# AE822FA0E5597BS0_CM55_HE_View register map
Vendor: Alif Semiconductor; Series: E8; File version: 1.0
CPU: CM55 r1p0, selectable endian, MPU, FPU, double-precision FPU, DSP, VTOR, 8 interrupt priority bits, 1 SAU regions
Registers are 32-bit, read-write, reset 0x0 unless marked. A register's access mark holds for its fields unless they carry their own. Offsets are from the block's base; [hi:lo] are bit positions; {n}, {i} and the like mark numbered series.

## CSI
Base 0x49033000
0x00 CSI_VERSION ro reset 0x30313534 — Module Version Code Register
  [31:0] VERSION — Module version code
0x04 CSI_N_LANES reset 0x1 — Lane Configuration Register
  [2:0] N_LANES — This can only be updated when the PHY lane is in Stop state. Number of active data lanes:
    0=1 Data Lane; 1=2 Data Lanes
0x08 CSI_CSI2_RESETN — CSI Controller Reset Control Register
  [0] CSI2_RESETN — CSI controller reset output. Active low.
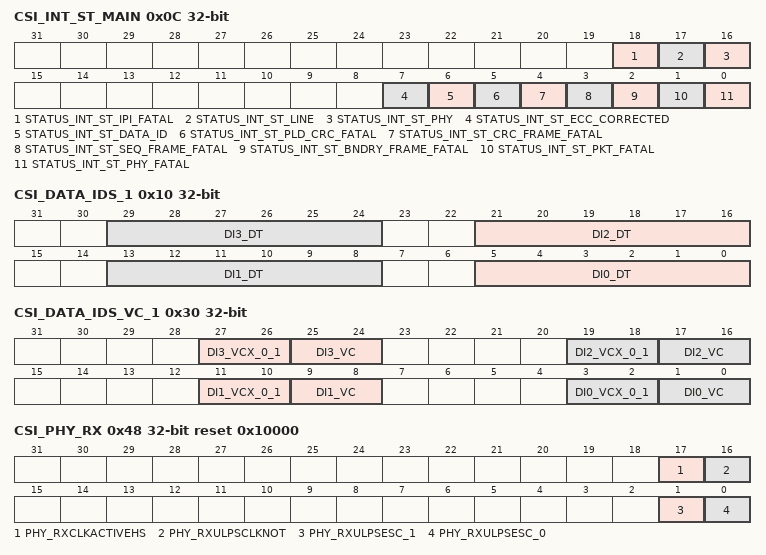
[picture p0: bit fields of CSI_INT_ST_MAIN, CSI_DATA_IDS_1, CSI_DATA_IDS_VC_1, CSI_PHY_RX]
0x0C CSI_INT_ST_MAIN ro — Main Interrupt Status Register
  [18] STATUS_INT_ST_IPI_FATAL read-clears — Status of INT_ST_IPI_FATAL.
  [17] STATUS_INT_ST_LINE read-clears — Status of INT_ST_LINE.
  [16] STATUS_INT_ST_PHY read-clears — Status of INT_ST_PHY.
  [7] STATUS_INT_ST_ECC_CORRECTED read-clears — Status of INT_ST_ECC_CORRECTED.
  [6] STATUS_INT_ST_DATA_ID read-clears — Status of INT_ST_DATA_ID.
  [5] STATUS_INT_ST_PLD_CRC_FATAL read-clears — Status of INT_ST_PLD_CRC_FATAL.
  [4] STATUS_INT_ST_CRC_FRAME_FATAL read-clears — Status of INT_ST_CRC_FRAME_FATAL.
  [3] STATUS_INT_ST_SEQ_FRAME_FATAL read-clears — Status of INT_ST_SEQ_FRAME_FATAL.
  [2] STATUS_INT_ST_BNDRY_FRAME_FATAL read-clears — Status of INT_ST_BNDRY_FRAME_FATAL.
  [1] STATUS_INT_ST_PKT_FATAL read-clears — Status of INT_ST_PKT_FATAL.
  [0] STATUS_INT_ST_PHY_FATAL read-clears — Status of INT_ST_PHY_FATAL.
0x10 CSI_DATA_IDS_1 — DT Data ID Monitors Configuration Register
  [8n+5:8n] DI{n}_DT (n=0..3) — Data type for programmed Data ID {n}.
0x30 CSI_DATA_IDS_VC_1 — VC Data ID Monitors Configuration Register
  [27:26] DI3_VCX_0_1 — Virtual channel extension for programmed Data ID 3.
  [8n+1:8n] DI{n}_VC (n=0..3) — Virtual channel for programmed Data ID {n}.
  [19:18] DI2_VCX_0_1 — Virtual channel extension for programmed Data ID 2.
  [11:10] DI1_VCX_0_1 — Virtual channel extension for programmed Data ID 1.
  [3:2] DI0_VCX_0_1 — Virtual channel extension for programmed data ID 0.
0x40 CSI_PHY_SHUTDOWNZ — PHY Shutdown Control Register
  [0] PHY_SHUTDOWNZ — Shutdown input. This line is used to place the complete PHY module in power down. All analog blocks are in power down mode and digital logic is cleared. Active low.
0x44 CSI_DPHY_RSTZ — PHY Reset Control Register
  [0] DPHY_RSTZ — PHY reset output. Active low.
0x48 CSI_PHY_RX ro reset 0x10000 — PHY RX Signals Status Register
  [17] PHY_RXCLKACTIVEHS — Indicates that D-PHY clock lane is actively receiving a DDR clock.
  [16] PHY_RXULPSCLKNOT — Active low. This signal indicates that D-PHY Clock Lane module has entered the Ultra Low Power State.
  [1] PHY_RXULPSESC_1 — Lane module 1 has entered the Ultra Low Power mode.
  [0] PHY_RXULPSESC_0 — Lane module 0 has entered the Ultra Low Power mode.
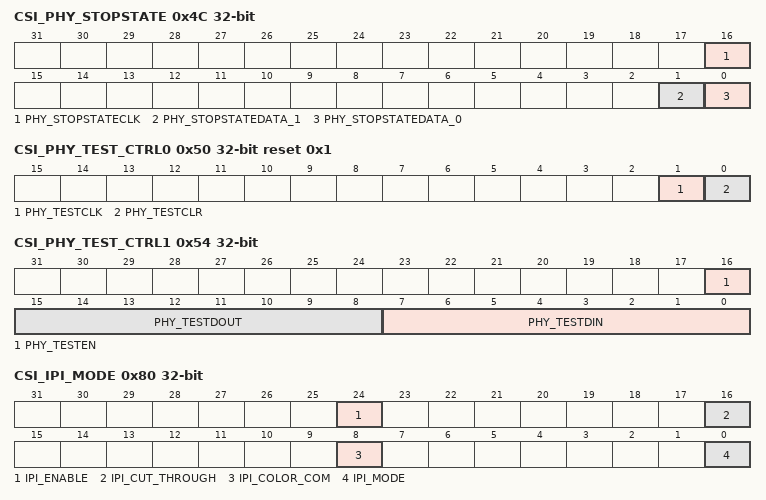
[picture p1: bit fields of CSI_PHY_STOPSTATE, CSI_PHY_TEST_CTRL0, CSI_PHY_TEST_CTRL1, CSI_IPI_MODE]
0x4C CSI_PHY_STOPSTATE ro — PHY STOPSTATE Signal Status Register
  [16] PHY_STOPSTATECLK — D-PHY Clock lane in Stop state.
  [1] PHY_STOPSTATEDATA_1 — Data lane 1 in Stop state.
  [0] PHY_STOPSTATEDATA_0 — Data lane 0 in Stop state.
0x50 CSI_PHY_TEST_CTRL0 reset 0x1 — PHY Test Control 0 Register
  [1] PHY_TESTCLK — Clock to capture TESTDIN bus contents into the PHY module, with TESTEN signal controlling the operation selection.
  [0] PHY_TESTCLR — When active, performs test interface initialization. Active high.
0x54 CSI_PHY_TEST_CTRL1 — PHY Test Control 1 Register
  [16] PHY_TESTEN — When asserted high, it configures an address write operation on the falling edge of TESTCLK. When asserted low, it configures a data write operation on the rising edge of TESTCLK.
  [15:8] PHY_TESTDOUT ro — Test interface 8-bit data output for reading data and other probing functionalities.
  [7:0] PHY_TESTDIN — Test interface 8-bit data input for programming internal registers and accessing test functionalities.
0x80 CSI_IPI_MODE — IPI Mode Selection Register
  [24] IPI_ENABLE — This register enables the interface.
  [16] IPI_CUT_THROUGH — This field indicates Cut-Through mode state:
    0=Cut-Through mode inactive; 1=Cut-Through mode active
  [8] IPI_COLOR_COM — This field indicates if color mode components are delivered as follows:
    0=48-bit interface; 1=16-bit interface
  [0] IPI_MODE — This field indicates the video mode transmission type as follows:
    0=Camera timing; 1=Controller timing
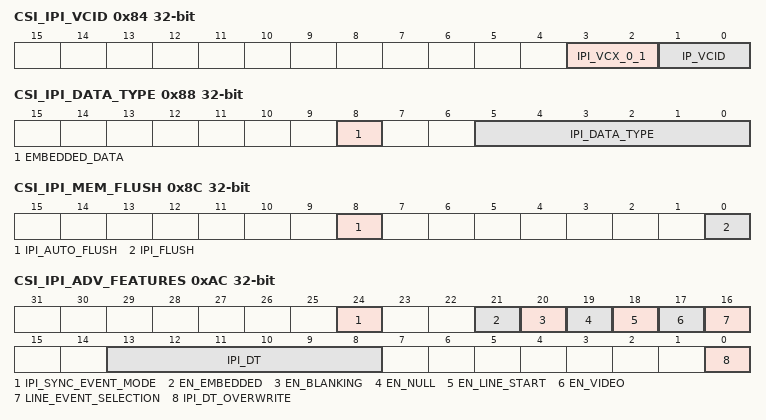
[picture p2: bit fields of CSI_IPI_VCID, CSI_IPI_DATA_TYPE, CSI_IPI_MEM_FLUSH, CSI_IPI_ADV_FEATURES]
0x84 CSI_IPI_VCID — IPI VC Selection Register
  [3:2] IPI_VCX_0_1 — Virtual channel extension of data to be processed by pixel interface.
  [1:0] IP_VCID — Virtual channel of data to be processed by pixel interface.
0x88 CSI_IPI_DATA_TYPE — IPI DT Selection Register
  [8] EMBEDDED_DATA — For Camera Timing Mode, this bit enables embedded data processing on IPI 1 interface.
  [5:0] IPI_DATA_TYPE — Data type of data to be processed by pixel interface 1.
0x8C CSI_IPI_MEM_FLUSH — IPI Memory Flush Control Register
  [8] IPI_AUTO_FLUSH — Memory is automatically flushed at each Frame Start.
  [0] IPI_FLUSH — Flush IPI memory. This bit is auto cleared.
0x90 CSI_IPI_HSA_TIME — IPI HSA Configuration Register
  [11:0] IPI_HSA_TIME — This field configures the HSA period in PIXCLK cycles.
0x94 CSI_IPI_HBP_TIME — IPI HBP Configuration Register
  [11:0] IPI_HBP_TIME — This field configures the HBP period in PIXCLK cycles.
0x98 CSI_IPI_HSD_TIME — IPI HSD Configuration Register
  [11:0] IPI_HSD_TIME — This field configures the Horizontal Sync Delay period in PIXCLK cycles.
0x9C CSI_IPI_HLINE_TIME — IPI HLINE Configuration Register
  [14:0] IPI_HLINE_TIME — This field configures the size of the line time counted in PIXCLK cycles.
0xA0 CSI_IPI_SOFTRSTN reset 0x1 — IPI Reset Control Register
  [0] IPI_SOFTRSTN — This field resets IPI. Active low.
0xAC CSI_IPI_ADV_FEATURES — IPI Advanced Features Configuration Register
  [24] IPI_SYNC_EVENT_MODE — For Camera Timing Mode:
    0=Frame Start does not trigger any sync event; 1=Legacy mode. Frame Start triggers a sync event.
  [21] EN_EMBEDDED — This field allows the use of embedded packets for IPI synchronization events.
  [20] EN_BLANKING — This field allows the use of blanking packets for IPI synchronization events.
  [19] EN_NULL — This field allows the use of null packets for IPI synchronization events.
  [18] EN_LINE_START — This field allows the use of line start packets for IPI synchronization events.
  [17] EN_VIDEO — This field allows the use of video packets for IPI synchronization events.
  [16] LINE_EVENT_SELECTION — For Camera Timing Mode, this field allows manual selection of the Packet for line delimiter as follows:
    0=Controller selects it automatically; 1=Select packets from list programmed in bits [21-17] of this register
  [13:8] IPI_DT — Data type to overwrite.
  [0] IPI_DT_OVERWRITE — Ignore Data type of the header using the programmed Data type for decoding.
0xB0 CSI_IPI_VSA_LINES — IPI VSA Configuration Register
  [9:0] IPI_VSA_LINES — This field configures the VSA period measured in number of horizontal lines.
0xB4 CSI_IPI_VBP_LINES — IPI VBP Configuration Register
  [9:0] IPI_VBP_LINES — This field configures the VBP period measured in number of horizontal lines.
0xB8 CSI_IPI_VFP_LINES — IPI VFP Configuration Register
  [9:0] IPI_VFP_LINES — This field configures the VFP period measured in number of horizontal lines.
0xBC CSI_IPI_VACTIVE_LINES — IPI VACTIVE Configuration Register
  [13:0] IPI_VACTIVE_LINES — This field configures the Vertical Active period measured in number of horizontal lines.
0xC8 CSI_VC_EXTENSION — VC Extension Configuration Register
  [0] VCX — This field indicates status of virtual channel extension:
    0=Virtual channel extension is enabled; 1=Legacy mode. Virtual channel extension is disabled.
0xCC CSI_PHY_CAL ro — PHY CALIBRATION Signal Status Register
  [0] RXSKEWCALHS read-clears — A low-to-high transition on RXSKEWCALHS signal means that the PHY has initiated the deskew calibration.
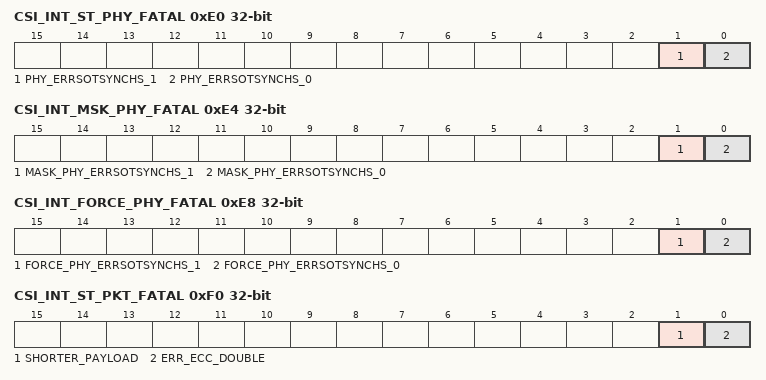
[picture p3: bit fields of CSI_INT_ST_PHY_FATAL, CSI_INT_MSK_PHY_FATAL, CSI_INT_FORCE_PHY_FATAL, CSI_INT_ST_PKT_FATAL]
0xE0 CSI_INT_ST_PHY_FATAL ro — PHY Packet Discarded Interrupt Status Register
  [1] PHY_ERRSOTSYNCHS_1 read-clears — Start of transmission error on data lane 1 (no synchronization achieved).
  [0] PHY_ERRSOTSYNCHS_0 read-clears — Start of transmission error on data lane 0 (no synchronization achieved).
0xE4 CSI_INT_MSK_PHY_FATAL — PHY Packet Discarded Interrupt Mask Register
  [1] MASK_PHY_ERRSOTSYNCHS_1 — Mask for PHY_ERRSOTSYNCHS_1.
  [0] MASK_PHY_ERRSOTSYNCHS_0 — Mask for PHY_ERRSOTSYNCHS_0.
0xE8 CSI_INT_FORCE_PHY_FATAL — PHY Packet Discarded Interrupt Force Register
  [1] FORCE_PHY_ERRSOTSYNCHS_1, [0] FORCE_PHY_ERRSOTSYNCHS_0
0xF0 CSI_INT_ST_PKT_FATAL ro — PHY Packet Construction Interrupt Status Register
  [1] SHORTER_PAYLOAD read-clears — D-PHY mode: Reported greater WC than received, unrecoverable.
  [0] ERR_ECC_DOUBLE read-clears — D-PHY mode: Header ECC contains at least 2 errors, unrecoverable.
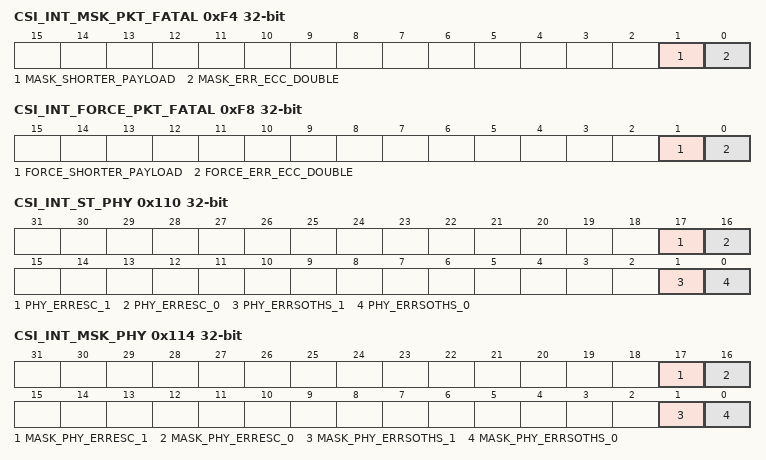
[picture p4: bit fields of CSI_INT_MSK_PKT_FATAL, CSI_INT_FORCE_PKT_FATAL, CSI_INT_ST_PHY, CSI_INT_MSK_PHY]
0xF4 CSI_INT_MSK_PKT_FATAL — PHY Packet Construction Interrupt Mask Register
  [1] MASK_SHORTER_PAYLOAD — Mask for SHORTER_PAYLOAD.
  [0] MASK_ERR_ECC_DOUBLE — Mask for ERR_ECC_DOUBLE.
0xF8 CSI_INT_FORCE_PKT_FATAL — PHY Packet Construction Interrupt Force Register
  [1] FORCE_SHORTER_PAYLOAD, [0] FORCE_ERR_ECC_DOUBLE
0x110 CSI_INT_ST_PHY ro — PHY Interrupt Status Register
  [17] PHY_ERRESC_1 read-clears — Escape Entry Error on data lane 1.
  [16] PHY_ERRESC_0 read-clears — Escape Entry Error on data lane 0.
  [1] PHY_ERRSOTHS_1 read-clears — Start of transmission error on data lane 1 (synchronization can still be achieved).
  [0] PHY_ERRSOTHS_0 read-clears — Start of transmission error on data lane 0 (synchronization can still be achieved).
0x114 CSI_INT_MSK_PHY — PHY Interrupt Mask Register
  [17] MASK_PHY_ERRESC_1 — Mask for PHY_ERRESC_1.
  [16] MASK_PHY_ERRESC_0 — Mask for PHY_ERRESC_0.
  [1] MASK_PHY_ERRSOTHS_1 — Mask for PHY_ERRSOTHS_1.
  [0] MASK_PHY_ERRSOTHS_0 — Mask for PHY_ERRSOTHS_0.
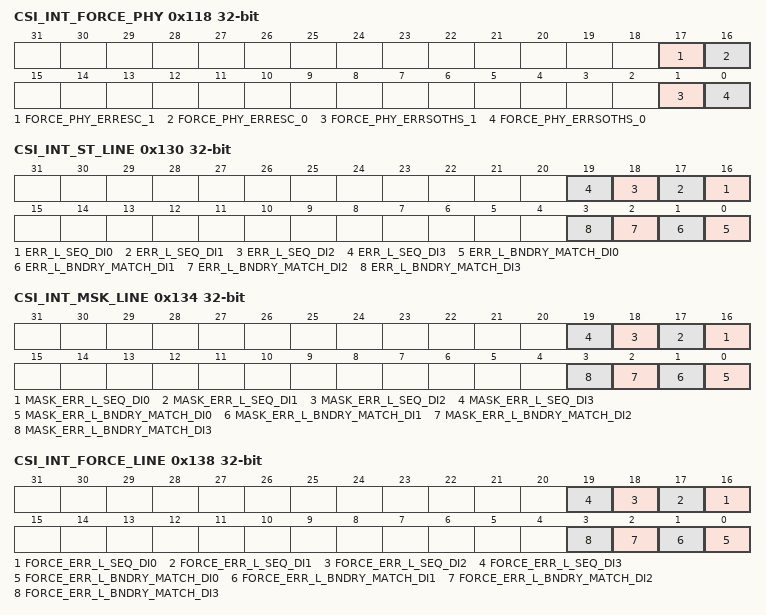
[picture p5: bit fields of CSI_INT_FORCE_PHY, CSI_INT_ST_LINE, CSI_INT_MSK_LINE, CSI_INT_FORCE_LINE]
0x118 CSI_INT_FORCE_PHY — PHY Interrupt Force Register
  [17] FORCE_PHY_ERRESC_1, [16] FORCE_PHY_ERRESC_0, [1] FORCE_PHY_ERRSOTHS_1, [0] FORCE_PHY_ERRSOTHS_0
0x130 CSI_INT_ST_LINE ro — PHY Line Construction Interrupt Status Register
  [n+16] ERR_L_SEQ_DI{n} read-clears (n=0..3) — Error in the sequence of lines for VC{n} and DT{n}.
  [n] ERR_L_BNDRY_MATCH_DI{n} read-clears (n=0..3) — Error matching line start with line end for VC{n} and DT{n}.
0x134 CSI_INT_MSK_LINE — PHY Line Construction Interrupt Mask Register
  [n+16] MASK_ERR_L_SEQ_DI{n} (n=0..3) — Mask for ERR_L_SEQ_DI{n}.
  [n] MASK_ERR_L_BNDRY_MATCH_DI{n} (n=0..3) — Mask for ERR_L_BNDRY_MATCH_DI{n}.
0x138 CSI_INT_FORCE_LINE — PHY Line Construction Interrupt Force Register
  [n+16] FORCE_ERR_L_SEQ_DI{n} (n=0..3), [n] FORCE_ERR_L_BNDRY_MATCH_DI{n} (n=0..3)
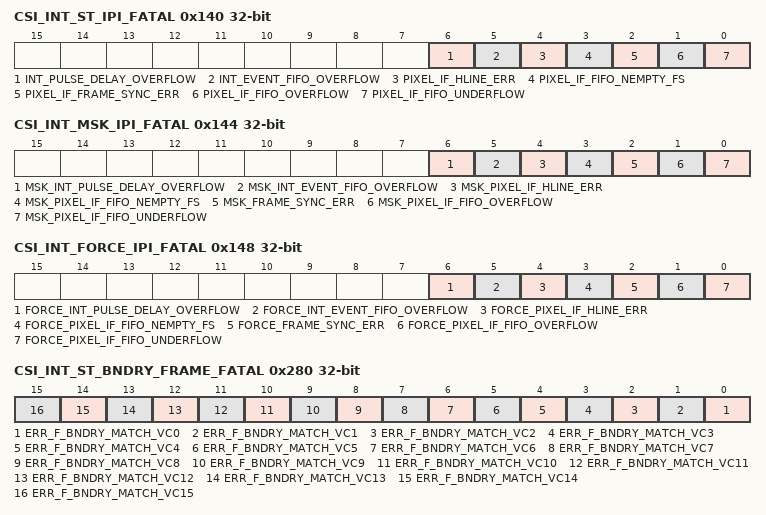
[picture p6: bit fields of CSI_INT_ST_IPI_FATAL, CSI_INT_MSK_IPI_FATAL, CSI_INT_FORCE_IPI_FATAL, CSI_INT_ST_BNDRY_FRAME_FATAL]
0x140 CSI_INT_ST_IPI_FATAL ro — IPI Interface Interrupt Status Register
  [6] INT_PULSE_DELAY_OVERFLOW read-clears — Reporting internal FIFO overflow on pulse delay block.
  [5] INT_EVENT_FIFO_OVERFLOW read-clears — Reporting internal FIFO overflow during IPI data processing.
  [4] PIXEL_IF_HLINE_ERR read-clears — Horizontal line time error (only available in Controller timing mode).
  [3] PIXEL_IF_FIFO_NEMPTY_FS read-clears — Controller timing mode: The FIFO of pixel interface is not empty at the start of a new frame. If this is expected this interrupt should be masked. Camera timing mode: The FIFO of pixel interface is not empty at the start of a new frame. There are some scenarios where synchronization events of new frame can be lost on IPI interface.
  [2] PIXEL_IF_FRAME_SYNC_ERR read-clears — Whenever in Controller timing mode, notifies if a new frame is received but previous has not been completed.
  [1] PIXEL_IF_FIFO_OVERFLOW read-clears — The FIFO of pixel interface has lost information because some data arrived and FIFO is already full.
  [0] PIXEL_IF_FIFO_UNDERFLOW read-clears — The FIFO has become empty before the expected number of pixels (calculated from the packet header) could be extracted to the pixel interface.
0x144 CSI_INT_MSK_IPI_FATAL — IPI Interface Interrupt Mask Register
  [6] MSK_INT_PULSE_DELAY_OVERFLOW — Mask for INT_PULSE_DELAY_OVERFLOW.
  [5] MSK_INT_EVENT_FIFO_OVERFLOW — Mask for INT_EVENT_FIFO_OVERFLOW.
  [4] MSK_PIXEL_IF_HLINE_ERR — Mask for PIXEL_IF_HLINE_ERR.
  [3] MSK_PIXEL_IF_FIFO_NEMPTY_FS — Mask for PIXEL_IF_FIFO_NEMPTY_FS.
  [2] MSK_FRAME_SYNC_ERR — Mask for PIXEL_IF_FRAME_SYNC_ERR.
  [1] MSK_PIXEL_IF_FIFO_OVERFLOW — Mask for PIXEL_IF_FIFO_OVERFLOW.
  [0] MSK_PIXEL_IF_FIFO_UNDERFLOW — Mask for PIXEL_IF_FIFO_UNDERFLOW.
0x148 CSI_INT_FORCE_IPI_FATAL — IPI Interface Interrupt Force Register
  [6] FORCE_INT_PULSE_DELAY_OVERFLOW — Force for INT_INT_PULSE_DELAY_OVERFLOW.
  [5] FORCE_INT_EVENT_FIFO_OVERFLOW — Force for INT_EVENT_FIFO_OVERFLOW.
  [4] FORCE_PIXEL_IF_HLINE_ERR — Force for PIXEL_IF_HLINE_ERR.
  [3] FORCE_PIXEL_IF_FIFO_NEMPTY_FS — Force for PIXEL_IF_FIFO_NEMPTY_FS.
  [2] FORCE_FRAME_SYNC_ERR — Force for FRAME_SYNC_ERR.
  [1] FORCE_PIXEL_IF_FIFO_OVERFLOW — Force for PIXEL_IF_FIFO_OVERFLOW.
  [0] FORCE_PIXEL_IF_FIFO_UNDERFLOW — Force for PIXEL_IF_FIFO_UNDERFLOW.
0x280 CSI_INT_ST_BNDRY_FRAME_FATAL ro — Frame Boundary Error Interrupt Status Register
  [n] ERR_F_BNDRY_MATCH_VC{n} read-clears (n=0..15) — Error matching Frame Start with Frame End for VC{n}.
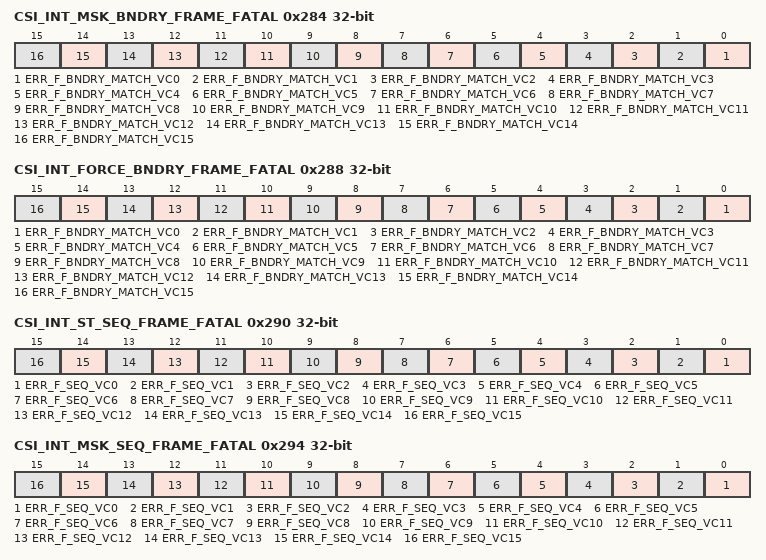
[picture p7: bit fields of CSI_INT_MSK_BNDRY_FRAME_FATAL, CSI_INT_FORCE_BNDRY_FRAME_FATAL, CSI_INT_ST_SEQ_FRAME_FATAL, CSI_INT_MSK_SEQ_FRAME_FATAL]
0x284 CSI_INT_MSK_BNDRY_FRAME_FATAL — Frame Boundary Error Interrupt Mask Register
  [n] ERR_F_BNDRY_MATCH_VC{n} (n=0..15) — Mask for ERR_F_BNDRY_MATCH_VC{n}.
0x288 CSI_INT_FORCE_BNDRY_FRAME_FATAL — Frame Boundary Error Interrupt Force Register
  [n] ERR_F_BNDRY_MATCH_VC{n} (n=0..15) — Force ERR_F_BNDRY_MATCH_VC{n}.
0x290 CSI_INT_ST_SEQ_FRAME_FATAL ro — Frame Sequence Error Interrupt Status Register
  [n] ERR_F_SEQ_VC{n} read-clears (n=0..15) — Incorrect Frame sequence detected in VC{n}.
0x294 CSI_INT_MSK_SEQ_FRAME_FATAL — Frame Sequence Error Interrupt Mask Register
  [n] ERR_F_SEQ_VC{n} (n=0..15) — Mask for ERR_F_SEQ_VC{n}.
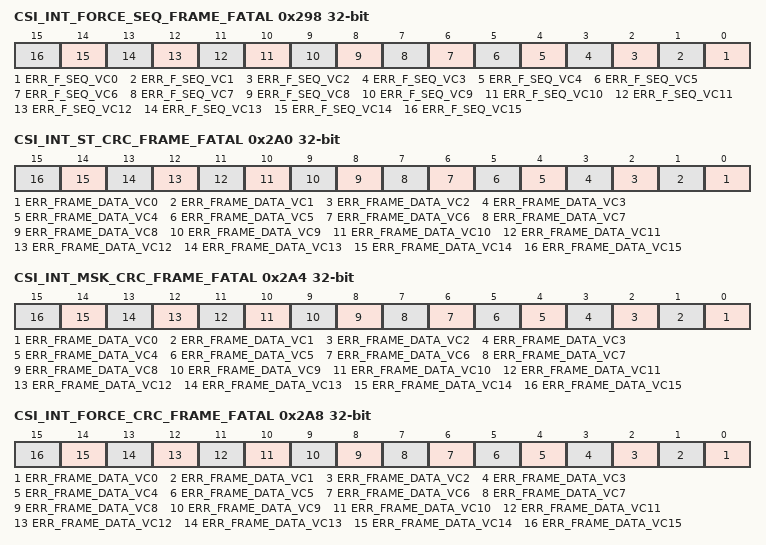
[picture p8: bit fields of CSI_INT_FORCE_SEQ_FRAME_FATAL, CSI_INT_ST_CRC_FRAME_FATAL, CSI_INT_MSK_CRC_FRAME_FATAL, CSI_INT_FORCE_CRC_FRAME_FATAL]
0x298 CSI_INT_FORCE_SEQ_FRAME_FATAL — Frame Sequence Error Interrupt Force Register
  [n] ERR_F_SEQ_VC{n} (n=0..15) — Force ERR_F_SEQ_VC{n}.
0x2A0 CSI_INT_ST_CRC_FRAME_FATAL ro — Frame CRC Error Interrupt Status Register
  [n] ERR_FRAME_DATA_VC{n} read-clears (n=0..15) — Last received Frame in VC{n}, had at least one CRC error.
0x2A4 CSI_INT_MSK_CRC_FRAME_FATAL — Frame CRC Error Interrupt Mask Register
  [n] ERR_FRAME_DATA_VC{n} (n=0..15) — Mask for ERR_FRAME_DATA_VC{n}.
0x2A8 CSI_INT_FORCE_CRC_FRAME_FATAL — Frame CRC Error Interrupt Force Register
  [n] ERR_FRAME_DATA_VC{n} (n=0..15) — Force ERR_FRAME_DATA_VC{n}.
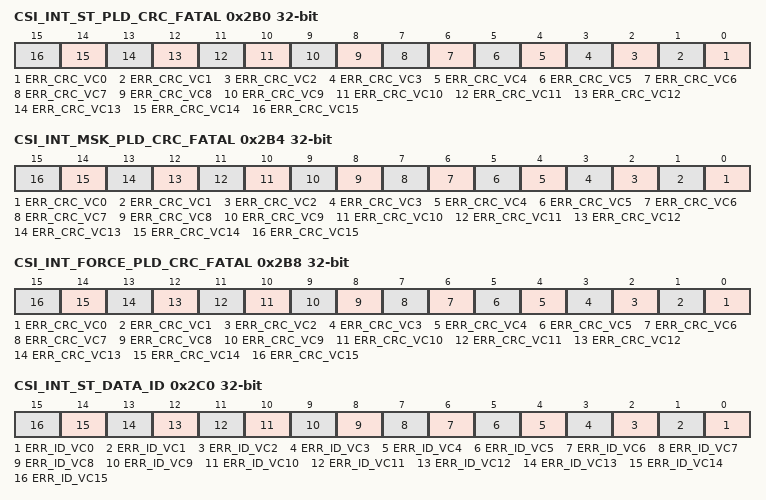
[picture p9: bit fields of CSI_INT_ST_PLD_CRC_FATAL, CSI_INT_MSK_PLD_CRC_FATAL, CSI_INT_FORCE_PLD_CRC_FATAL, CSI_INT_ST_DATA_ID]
0x2B0 CSI_INT_ST_PLD_CRC_FATAL ro — Frame Payload Error Interrupt Status Register
  [n] ERR_CRC_VC{n} read-clears (n=0..15) — Payload Checksum error detected on VC{n}.
0x2B4 CSI_INT_MSK_PLD_CRC_FATAL — Frame Payload Error Interrupt Mask Register
  [n] ERR_CRC_VC{n} (n=0..15) — Mask for ERR_CRC_VC{n}.
0x2B8 CSI_INT_FORCE_PLD_CRC_FATAL — Frame Payload Error Interrupt Force Register
  [n] ERR_CRC_VC{n} (n=0..15) — Force ERR_CRC_VC{n}.
0x2C0 CSI_INT_ST_DATA_ID ro — DT Error Interrupt Status Register
  [n] ERR_ID_VC{n} read-clears (n=0..15) — Unrecognized or unimplemented data type detected in VC{n}.
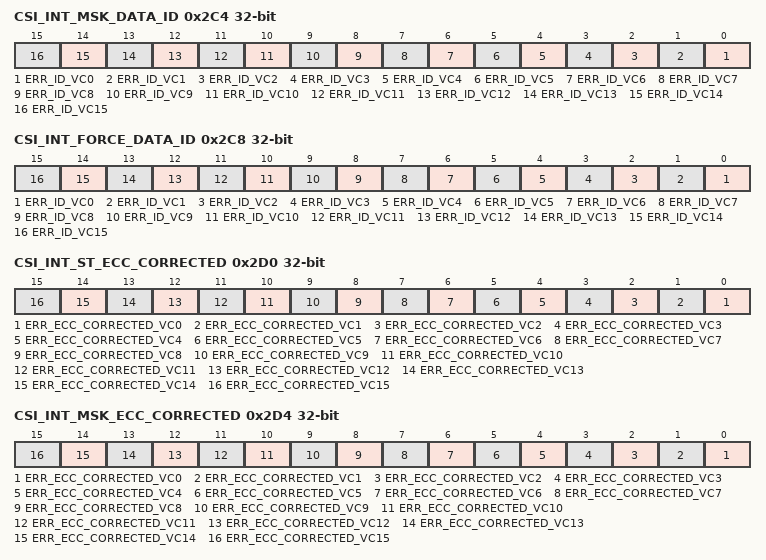
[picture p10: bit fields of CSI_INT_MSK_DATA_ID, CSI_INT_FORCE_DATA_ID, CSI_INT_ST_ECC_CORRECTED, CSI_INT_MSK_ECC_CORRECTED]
0x2C4 CSI_INT_MSK_DATA_ID — DT Error Interrupt Mask Register
  [n] ERR_ID_VC{n} (n=0..15) — Mask for ERR_ID_VC{n}.
0x2C8 CSI_INT_FORCE_DATA_ID — DT Error Interrupt Force Register
  [n] ERR_ID_VC{n} (n=0..15) — Force ERR_ID_VC{n}.
0x2D0 CSI_INT_ST_ECC_CORRECTED ro — ECC Interrupt Status Register
  [n] ERR_ECC_CORRECTED_VC{n} read-clears (n=0..15) — D-PHY mode: Header error detected and corrected on VC{n}.
0x2D4 CSI_INT_MSK_ECC_CORRECTED — ECC Interrupt Mask Register
  [n] ERR_ECC_CORRECTED_VC{n} (n=0..15) — Mask for ERR_ECC_CORRECTED_VC{n}.
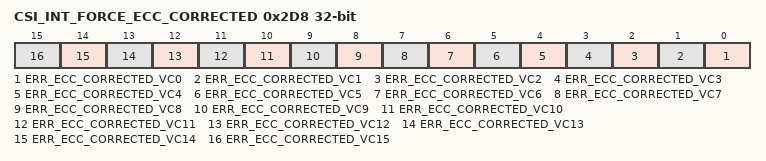
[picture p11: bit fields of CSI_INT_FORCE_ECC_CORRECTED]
0x2D8 CSI_INT_FORCE_ECC_CORRECTED — ECC Interrupt Force Register
  [n] ERR_ECC_CORRECTED_VC{n} (n=0..15) — Force ERR_ECC_CORRECTED_VC{n}.
0x300 CSI_SCRAMBLING — Descrambling Control Register
  [0] SCRAMBLE_ENABLE — Enables data descrambling on the CSI controller side.
0x304 CSI_SCRAMBLING_SEED1 reset 0x1008 — Descrambling Seed Configuration Lane 0 Register
  [15:0] SCRAMBLE_SEED_LANE1 — Seed used by descrambler block for lane 1.
0x308 CSI_SCRAMBLING_SEED2 reset 0x1188 — Descrambling Seed Configuration Lane 1 Register
  [15:0] SCRAMBLE_SEED_LANE2 — Seed used by descrambler block for lane 2.
